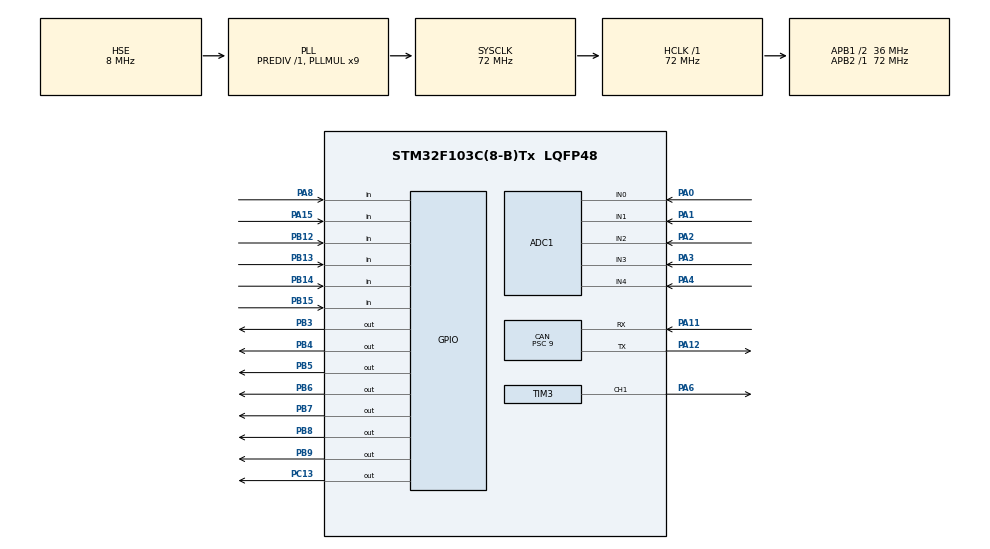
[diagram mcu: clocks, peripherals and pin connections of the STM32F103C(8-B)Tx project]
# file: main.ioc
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ADC1.Channel-4\#ChannelRegularConversion=ADC_CHANNEL_0
ADC1.Channel-5\#ChannelRegularConversion=ADC_CHANNEL_1
ADC1.Channel-6\#ChannelRegularConversion=ADC_CHANNEL_2
ADC1.Channel-7\#ChannelRegularConversion=ADC_CHANNEL_3
ADC1.Channel-8\#ChannelRegularConversion=ADC_CHANNEL_4
ADC1.ContinuousConvMode=ENABLE
ADC1.DataAlign=ADC_DATAALIGN_RIGHT
ADC1.DiscontinuousConvMode=DISABLE
ADC1.EnableRegularConversion=ENABLE
ADC1.ExternalTrigConv=ADC_SOFTWARE_START
ADC1.NbrOfConversion=5
ADC1.NbrOfConversionFlag=1
ADC1.Rank-4\#ChannelRegularConversion=1
ADC1.Rank-5\#ChannelRegularConversion=2
ADC1.Rank-6\#ChannelRegularConversion=3
ADC1.Rank-7\#ChannelRegularConversion=4
ADC1.Rank-8\#ChannelRegularConversion=5
ADC1.SamplingTime-4\#ChannelRegularConversion=ADC_SAMPLETIME_239CYCLES_5
ADC1.SamplingTime-5\#ChannelRegularConversion=ADC_SAMPLETIME_239CYCLES_5
ADC1.SamplingTime-6\#ChannelRegularConversion=ADC_SAMPLETIME_239CYCLES_5
ADC1.SamplingTime-7\#ChannelRegularConversion=ADC_SAMPLETIME_239CYCLES_5
ADC1.SamplingTime-8\#ChannelRegularConversion=ADC_SAMPLETIME_239CYCLES_5
ADC1.master=1
CAN.BS1=CAN_BS1_3TQ
CAN.BS2=CAN_BS2_4TQ
CAN.CalculateTimeBit=2000
CAN.CalculateTimeQuantum=250.0
CAN.Prescaler=9
CAN.TXFP=DISABLE
Dma.ADC1.0.Direction=DMA_PERIPH_TO_MEMORY
Dma.ADC1.0.Instance=DMA1_Channel1
Dma.ADC1.0.MemDataAlignment=DMA_MDATAALIGN_HALFWORD
Dma.ADC1.0.MemInc=DMA_MINC_ENABLE
Dma.ADC1.0.Mode=DMA_CIRCULAR
Dma.ADC1.0.PeriphDataAlignment=DMA_PDATAALIGN_HALFWORD
Dma.ADC1.0.PeriphInc=DMA_PINC_DISABLE
Dma.ADC1.0.Priority=DMA_PRIORITY_LOW
Dma.Request0=ADC1
Mcu.Family=STM32F1
Mcu.Name=STM32F103C(8-B)Tx
Mcu.Package=LQFP48
NVIC.DMA1_Channel1_IRQn=true\:15\:0\:true\:false\:true\:false\:true
NVIC.PriorityGroup=NVIC_PRIORITYGROUP_4
NVIC.USB_LP_CAN1_RX0_IRQn=true\:8\:0\:true\:false\:true\:true\:true
PA0-WKUP.Signal=ADCx_IN0
PA1.Signal=ADCx_IN1
PA11.Mode=Master
PA11.Signal=CAN_RX
PA12.Mode=Master
PA12.Signal=CAN_TX
PA13.Mode=Serial_Wire
PA13.Signal=SYS_JTMS-SWDIO
PA14.Mode=Serial_Wire
PA14.Signal=SYS_JTCK-SWCLK
PA15.Signal=GPIO_Input
PA2.Signal=ADCx_IN2
PA3.Signal=ADCx_IN3
PA4.Signal=ADCx_IN4
PA6.Signal=S_TIM3_CH1
PA8.Signal=GPIO_Input
PB12.Signal=GPIO_Input
PB13.Signal=GPIO_Input
PB14.Signal=GPIO_Input
PB15.Signal=GPIO_Input
PB3.GPIO_ModeDefaultOutputPP=GPIO_MODE_OUTPUT_PP
PB3.GPIO_PuPd=GPIO_NOPULL
PB3.PinState=GPIO_PIN_RESET
PB3.Signal=GPIO_Output
PB4.Signal=GPIO_Output
PB5.Signal=GPIO_Output
PB6.Signal=GPIO_Output
PB7.Signal=GPIO_Output
PB8.Signal=GPIO_Output
PB9.Signal=GPIO_Output
PC13-TAMPER-RTC.Signal=GPIO_Output
PD0-OSC_IN.Mode=HSE-External-Oscillator
PD0-OSC_IN.Signal=RCC_OSC_IN
PD1-OSC_OUT.Mode=HSE-External-Oscillator
PD1-OSC_OUT.Signal=RCC_OSC_OUT
ProjectManager.HeapSize=0x200
ProjectManager.StackSize=0x400
ProjectManager.TargetToolchain=Makefile
RCC.ADCPresc=RCC_ADCPCLK2_DIV6
RCC.AHBFreq_Value=72000000
RCC.APB1CLKDivider=RCC_HCLK_DIV2
RCC.APB1Freq_Value=36000000
RCC.APB1TimFreq_Value=72000000
RCC.APB2Freq_Value=72000000
RCC.APB2TimFreq_Value=72000000
RCC.EnbaleCSS=true
RCC.HCLKFreq_Value=72000000
RCC.PLLMUL=RCC_PLL_MUL9
RCC.PLLSourceVirtual=RCC_PLLSOURCE_HSE
RCC.SYSCLKFreq_VALUE=72000000
RCC.SYSCLKSource=RCC_SYSCLKSOURCE_PLLCLK
RCC.USBFreq_Value=72000000
SH.ADCx_IN0.0=ADC1_IN0,IN0
SH.ADCx_IN1.0=ADC1_IN1,IN1
SH.ADCx_IN2.0=ADC1_IN2,IN2
SH.ADCx_IN3.0=ADC1_IN3,IN3
SH.ADCx_IN4.0=ADC1_IN4,IN4
SH.S_TIM3_CH1.0=TIM3_CH1,PWM Generation1 CH1
TIM3.AutoReloadPreload=TIM_AUTORELOAD_PRELOAD_ENABLE
TIM3.Channel-PWM\ Generation1\ CH1=TIM_CHANNEL_1
TIM3.Period=65535
VP_TIM3_VS_ClockSourceINT.Mode=Internal
board=custom

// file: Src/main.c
/* USER CODE BEGIN Header */
/**
  ******************************************************************************
  * @file           : main.c
  * @brief          : Main program body
  ******************************************************************************
  * @attention
  *
  * <h2><center>&copy; Copyright (c) 2020 STMicroelectronics.
  * All rights reserved.</center></h2>
  *
  * This software component is licensed by ST under BSD 3-Clause license,
  * the "License"; You may not use this file except in compliance with the
  * License. You may obtain a copy of the License at:
  *                        opensource.org/licenses/BSD-3-Clause
  *
  ******************************************************************************
  */
/* USER CODE END Header */

#include "main.h"
#include "adc.h"
#include "can.h"
#include "dma.h"
#include "tim.h"
#include "gpio.h"

/* USER CODE BEGIN Includes */
#include "delay.h"
/*#include "lights.h"*/
#include "engine.c"
#include "obd.h"
#include "sensor.h"
#include "cooling.h"
/* USER CODE END Includes */

void SystemClock_Config(void);

int main(void)
{

  /* MCU Configuration--------------------------------------------------------*/

  /* Reset of all peripherals, Initializes the Flash interface and the Systick. */
  HAL_Init();

  /* Configure the system clock */
  SystemClock_Config();

  /* Initialize all configured peripherals */
  MX_GPIO_Init();
  MX_DMA_Init();
  MX_CAN_Init();
  MX_ADC1_Init();
  MX_TIM3_Init();
  /* USER CODE BEGIN 2 */
  DWT_Init();
  /* USER CODE END 2 */

  /* Infinite loop */
  /* USER CODE BEGIN WHILE */
  ECU_OBD_Init();
  ECU_Sensor_Init();
  ECU_Cooling_Init();
  ECU_Engine_Init();
  while(1) {

    //ECU_Engine_Check();
    ECU_Cooling_Check();
    ECU_OBD_Check();

    /* USER CODE END WHILE */

  }
}

void SystemClock_Config(void)
{
  RCC_OscInitTypeDef RCC_OscInitStruct = {0};
  RCC_ClkInitTypeDef RCC_ClkInitStruct = {0};
  RCC_PeriphCLKInitTypeDef PeriphClkInit = {0};

  /** Initializes the CPU, AHB and APB busses clocks
  */
  RCC_OscInitStruct.OscillatorType = RCC_OSCILLATORTYPE_HSE;
  RCC_OscInitStruct.HSEState = RCC_HSE_ON;
  RCC_OscInitStruct.HSEPredivValue = RCC_HSE_PREDIV_DIV1;
  RCC_OscInitStruct.HSIState = RCC_HSI_ON;
  RCC_OscInitStruct.PLL.PLLState = RCC_PLL_ON;
  RCC_OscInitStruct.PLL.PLLSource = RCC_PLLSOURCE_HSE;
  RCC_OscInitStruct.PLL.PLLMUL = RCC_PLL_MUL9;
  if (HAL_RCC_OscConfig(&RCC_OscInitStruct) != HAL_OK)
  {
    Error_Handler();
  }
  /** Initializes the CPU, AHB and APB busses clocks
  */
  RCC_ClkInitStruct.ClockType = RCC_CLOCKTYPE_HCLK|RCC_CLOCKTYPE_SYSCLK
                              |RCC_CLOCKTYPE_PCLK1|RCC_CLOCKTYPE_PCLK2;
  RCC_ClkInitStruct.SYSCLKSource = RCC_SYSCLKSOURCE_PLLCLK;
  RCC_ClkInitStruct.AHBCLKDivider = RCC_SYSCLK_DIV1;
  RCC_ClkInitStruct.APB1CLKDivider = RCC_HCLK_DIV2;
  RCC_ClkInitStruct.APB2CLKDivider = RCC_HCLK_DIV1;

  if (HAL_RCC_ClockConfig(&RCC_ClkInitStruct, FLASH_LATENCY_2) != HAL_OK)
  {
    Error_Handler();
  }
  PeriphClkInit.PeriphClockSelection = RCC_PERIPHCLK_ADC;
  PeriphClkInit.AdcClockSelection = RCC_ADCPCLK2_DIV6;
  if (HAL_RCCEx_PeriphCLKConfig(&PeriphClkInit) != HAL_OK)
  {
    Error_Handler();
  }
  /** Enables the Clock Security System
  */
  //HAL_RCC_EnableCSS();
}

void Error_Handler(void)
{
}

/************************ (C) COPYRIGHT STMicroelectronics *****END OF FILE****/
